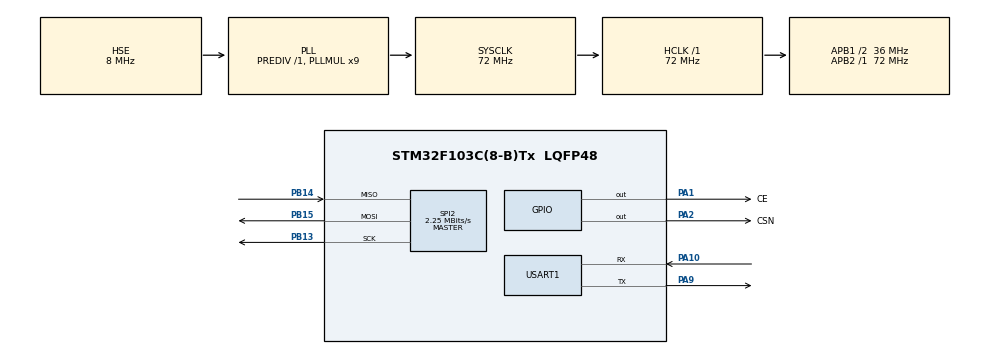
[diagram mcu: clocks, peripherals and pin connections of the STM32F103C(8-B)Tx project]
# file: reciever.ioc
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Mcu.Family=STM32F1
Mcu.Name=STM32F103C(8-B)Tx
Mcu.Package=LQFP48
NVIC.PriorityGroup=NVIC_PRIORITYGROUP_4
PA1.GPIO_Label=CE
PA1.Signal=GPIO_Output
PA10.Mode=Asynchronous
PA10.Signal=USART1_RX
PA13.Mode=Serial_Wire
PA13.Signal=SYS_JTMS-SWDIO
PA14.Mode=Serial_Wire
PA14.Signal=SYS_JTCK-SWCLK
PA2.GPIO_Label=CSN
PA2.Signal=GPIO_Output
PA9.Mode=Asynchronous
PA9.Signal=USART1_TX
PB13.Mode=Full_Duplex_Master
PB13.Signal=SPI2_SCK
PB14.Mode=Full_Duplex_Master
PB14.Signal=SPI2_MISO
PB15.Mode=Full_Duplex_Master
PB15.Signal=SPI2_MOSI
PD0-OSC_IN.Mode=HSE-External-Oscillator
PD0-OSC_IN.Signal=RCC_OSC_IN
PD1-OSC_OUT.Mode=HSE-External-Oscillator
PD1-OSC_OUT.Signal=RCC_OSC_OUT
ProjectManager.HeapSize=0x200
ProjectManager.StackSize=0x400
ProjectManager.TargetToolchain=MDK-ARM V5
RCC.AHBFreq_Value=72000000
RCC.APB1CLKDivider=RCC_HCLK_DIV2
RCC.APB1Freq_Value=36000000
RCC.APB1TimFreq_Value=72000000
RCC.APB2Freq_Value=72000000
RCC.APB2TimFreq_Value=72000000
RCC.HCLKFreq_Value=72000000
RCC.PLLMUL=RCC_PLL_MUL9
RCC.PLLSourceVirtual=RCC_PLLSOURCE_HSE
RCC.SYSCLKFreq_VALUE=72000000
RCC.SYSCLKSource=RCC_SYSCLKSOURCE_PLLCLK
RCC.USBFreq_Value=72000000
SPI2.BaudRatePrescaler=SPI_BAUDRATEPRESCALER_16
SPI2.CalculateBaudRate=2.25 MBits/s
SPI2.Direction=SPI_DIRECTION_2LINES
SPI2.Mode=SPI_MODE_MASTER
SPI2.VirtualType=VM_MASTER
USART1.VirtualMode=VM_ASYNC
board=custom

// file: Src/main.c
/**
  ******************************************************************************
  * @file           : main.c
  * @brief          : Main program body
  ******************************************************************************
  ** This notice applies to any and all portions of this file
  * that are not between comment pairs USER CODE BEGIN and
  * USER CODE END. Other portions of this file, whether
  * inserted by the user or by software development tools
  * are owned by their respective copyright owners.
  *
  * COPYRIGHT(c) 2019 STMicroelectronics
  *
  * Redistribution and use in source and binary forms, with or without modification,
  * are permitted provided that the following conditions are met:
  *   1. Redistributions of source code must retain the above copyright notice,
  *      this list of conditions and the following disclaimer.
  *   2. Redistributions in binary form must reproduce the above copyright notice,
  *      this list of conditions and the following disclaimer in the documentation
  *      and/or other materials provided with the distribution.
  *   3. Neither the name of STMicroelectronics nor the names of its contributors
  *      may be used to endorse or promote products derived from this software
  *      without specific prior written permission.
  *
  * THIS SOFTWARE IS PROVIDED BY THE COPYRIGHT HOLDERS AND CONTRIBUTORS "AS IS"
  * AND ANY EXPRESS OR IMPLIED WARRANTIES, INCLUDING, BUT NOT LIMITED TO, THE
  * IMPLIED WARRANTIES OF MERCHANTABILITY AND FITNESS FOR A PARTICULAR PURPOSE ARE
  * DISCLAIMED. IN NO EVENT SHALL THE COPYRIGHT HOLDER OR CONTRIBUTORS BE LIABLE
  * FOR ANY DIRECT, INDIRECT, INCIDENTAL, SPECIAL, EXEMPLARY, OR CONSEQUENTIAL
  * DAMAGES (INCLUDING, BUT NOT LIMITED TO, PROCUREMENT OF SUBSTITUTE GOODS OR
  * SERVICES; LOSS OF USE, DATA, OR PROFITS; OR BUSINESS INTERRUPTION) HOWEVER
  * CAUSED AND ON ANY THEORY OF LIABILITY, WHETHER IN CONTRACT, STRICT LIABILITY,
  * OR TORT (INCLUDING NEGLIGENCE OR OTHERWISE) ARISING IN ANY WAY OUT OF THE USE
  * OF THIS SOFTWARE, EVEN IF ADVISED OF THE POSSIBILITY OF SUCH DAMAGE.
  *
  ******************************************************************************
  */
#include "main.h"
#include "stm32f1xx_hal.h"

/* USER CODE BEGIN Includes */
#include "string.h"
/* USER CODE END Includes */

SPI_HandleTypeDef hspi2;

UART_HandleTypeDef huart1;

/* USER CODE BEGIN PV */
/* Private variables ---------------------------------------------------------*/
char data[50];
/* USER CODE END PV */

void SystemClock_Config(void);
static void MX_GPIO_Init(void);
static void MX_SPI2_Init(void);
static void MX_USART1_UART_Init(void);

/* USER CODE BEGIN PFP */
/* Private function prototypes -----------------------------------------------*/

/* USER CODE END PFP */

int main(void)
{

  /* MCU Configuration----------------------------------------------------------*/

  /* Reset of all peripherals, Initializes the Flash interface and the Systick. */
  HAL_Init();

  /* Configure the system clock */
  SystemClock_Config();

  /* Initialize all configured peripherals */
  MX_GPIO_Init();
  MX_SPI2_Init();
  MX_USART1_UART_Init();

  /* Infinite loop */
  while (1)
  {

  }

}

void SystemClock_Config(void)
{

  RCC_OscInitTypeDef RCC_OscInitStruct;
  RCC_ClkInitTypeDef RCC_ClkInitStruct;

    /**Initializes the CPU, AHB and APB busses clocks
    */
  RCC_OscInitStruct.OscillatorType = RCC_OSCILLATORTYPE_HSE;
  RCC_OscInitStruct.HSEState = RCC_HSE_ON;
  RCC_OscInitStruct.HSEPredivValue = RCC_HSE_PREDIV_DIV1;
  RCC_OscInitStruct.HSIState = RCC_HSI_ON;
  RCC_OscInitStruct.PLL.PLLState = RCC_PLL_ON;
  RCC_OscInitStruct.PLL.PLLSource = RCC_PLLSOURCE_HSE;
  RCC_OscInitStruct.PLL.PLLMUL = RCC_PLL_MUL9;
  if (HAL_RCC_OscConfig(&RCC_OscInitStruct) != HAL_OK)
  {
    _Error_Handler(__FILE__, __LINE__);
  }

    /**Initializes the CPU, AHB and APB busses clocks
    */
  RCC_ClkInitStruct.ClockType = RCC_CLOCKTYPE_HCLK|RCC_CLOCKTYPE_SYSCLK
                              |RCC_CLOCKTYPE_PCLK1|RCC_CLOCKTYPE_PCLK2;
  RCC_ClkInitStruct.SYSCLKSource = RCC_SYSCLKSOURCE_PLLCLK;
  RCC_ClkInitStruct.AHBCLKDivider = RCC_SYSCLK_DIV1;
  RCC_ClkInitStruct.APB1CLKDivider = RCC_HCLK_DIV2;
  RCC_ClkInitStruct.APB2CLKDivider = RCC_HCLK_DIV1;

  if (HAL_RCC_ClockConfig(&RCC_ClkInitStruct, FLASH_LATENCY_2) != HAL_OK)
  {
    _Error_Handler(__FILE__, __LINE__);
  }

    /**Configure the Systick interrupt time
    */
  HAL_SYSTICK_Config(HAL_RCC_GetHCLKFreq()/1000);

    /**Configure the Systick
    */
  HAL_SYSTICK_CLKSourceConfig(SYSTICK_CLKSOURCE_HCLK);

  /* SysTick_IRQn interrupt configuration */
  HAL_NVIC_SetPriority(SysTick_IRQn, 0, 0);
}

/* SPI2 init function */
static void MX_SPI2_Init(void)
{

  /* SPI2 parameter configuration*/
  hspi2.Instance = SPI2;
  hspi2.Init.Mode = SPI_MODE_MASTER;
  hspi2.Init.Direction = SPI_DIRECTION_2LINES;
  hspi2.Init.DataSize = SPI_DATASIZE_8BIT;
  hspi2.Init.CLKPolarity = SPI_POLARITY_LOW;
  hspi2.Init.CLKPhase = SPI_PHASE_1EDGE;
  hspi2.Init.NSS = SPI_NSS_SOFT;
  hspi2.Init.BaudRatePrescaler = SPI_BAUDRATEPRESCALER_16;
  hspi2.Init.FirstBit = SPI_FIRSTBIT_MSB;
  hspi2.Init.TIMode = SPI_TIMODE_DISABLE;
  hspi2.Init.CRCCalculation = SPI_CRCCALCULATION_DISABLE;
  hspi2.Init.CRCPolynomial = 10;
  if (HAL_SPI_Init(&hspi2) != HAL_OK)
  {
    _Error_Handler(__FILE__, __LINE__);
  }

}

/* USART1 init function */
static void MX_USART1_UART_Init(void)
{

  huart1.Instance = USART1;
  huart1.Init.BaudRate = 115200;
  huart1.Init.WordLength = UART_WORDLENGTH_8B;
  huart1.Init.StopBits = UART_STOPBITS_1;
  huart1.Init.Parity = UART_PARITY_NONE;
  huart1.Init.Mode = UART_MODE_TX_RX;
  huart1.Init.HwFlowCtl = UART_HWCONTROL_NONE;
  huart1.Init.OverSampling = UART_OVERSAMPLING_16;
  if (HAL_UART_Init(&huart1) != HAL_OK)
  {
    _Error_Handler(__FILE__, __LINE__);
  }

}

/** Configure pins as
        * Analog
        * Input
        * Output
        * EVENT_OUT
        * EXTI
*/
static void MX_GPIO_Init(void)
{

  GPIO_InitTypeDef GPIO_InitStruct;

  /* GPIO Ports Clock Enable */
  __HAL_RCC_GPIOD_CLK_ENABLE();
  __HAL_RCC_GPIOA_CLK_ENABLE();
  __HAL_RCC_GPIOB_CLK_ENABLE();

  /*Configure GPIO pin Output Level */
  HAL_GPIO_WritePin(GPIOA, CE_Pin|CSN_Pin, GPIO_PIN_RESET);

  /*Configure GPIO pins : CE_Pin CSN_Pin */
  GPIO_InitStruct.Pin = CE_Pin|CSN_Pin;
  GPIO_InitStruct.Mode = GPIO_MODE_OUTPUT_PP;
  GPIO_InitStruct.Pull = GPIO_NOPULL;
  GPIO_InitStruct.Speed = GPIO_SPEED_FREQ_LOW;
  HAL_GPIO_Init(GPIOA, &GPIO_InitStruct);

}

void _Error_Handler(char *file, int line)
{
  while(1)
  {
  }
}

/************************ (C) COPYRIGHT STMicroelectronics *****END OF FILE****/
